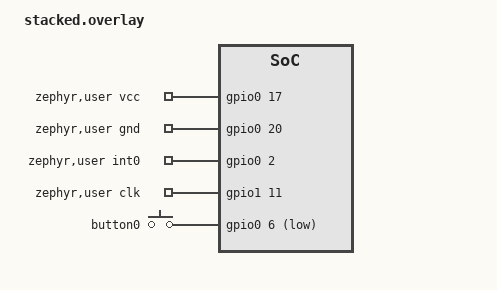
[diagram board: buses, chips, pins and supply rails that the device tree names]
// Stacked board overlay configuration for the Supermini UF2 board

// The imu is stacked on top of the supermini_uf2 board
//    Power is provided via GPIO pins (pin 17 as HIGH), (pin 20 as LOW) 
//    CLK  is configured to be adjacent to the CLK_CTL input on the imu
//    INT0 is configured to be adjacent to the INT0    input on the imu


&button0 {
    gpios = <&gpio0 6 (GPIO_PULL_UP | GPIO_ACTIVE_LOW)>;
};

/ {
    aliases {
		sw0 = &button0;
	};

	zephyr,user {
        // vcc and ground pins for imu
        vcc_gpios = <&gpio0 17 GPIO_OPEN_SOURCE>;
        gnd_gpios = <&gpio0 20 GPIO_OPEN_DRAIN>;

        // Interrupt adjacent to INT pin on imu (Not required, needed for Wake on Motion (WOM) aka "sleep")
        int0-gpios = <&gpio0 2 0>;

        // Clock adjacent to CLK_CTL pin on imu (comment out to disable)
		clk-gpios = <&gpio1 11 GPIO_OPEN_DRAIN>; 
	};

};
